VERSION "1"

NS_ :

BS_:

BU_: User ADM_PC_LF45

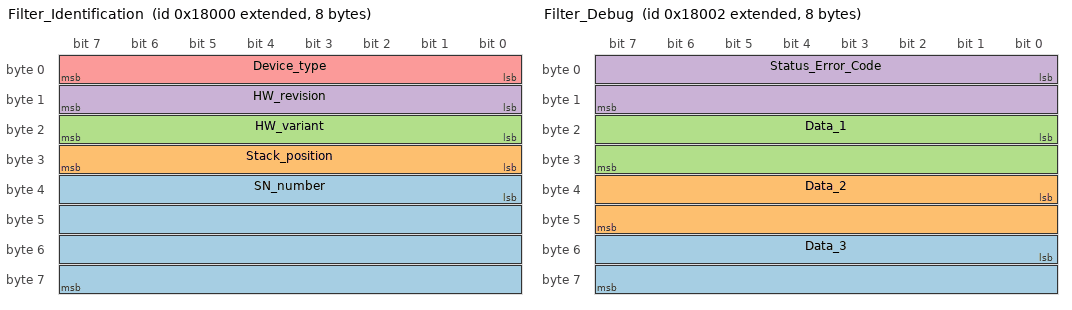
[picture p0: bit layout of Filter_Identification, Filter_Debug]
BO_ 2147581952 Filter_Identification: 8 ADM_PC_LF45
 SG_ SN_number : 32|32@1+ (1,0) [0|0] "" Vector__XXX
 SG_ Stack_position : 24|8@1+ (1,0) [0|0] "" Vector__XXX
 SG_ HW_variant : 16|8@1+ (1,0) [0|0] "" Vector__XXX
 SG_ HW_revision : 8|8@1+ (1,0) [0|0] "" Vector__XXX
 SG_ Device_type : 0|8@1+ (1,0) [0|0] "" Vector__XXX

BO_ 2147581953 Filter_FwInfo: 8 ADM_PC_LF45
 SG_ FW_info_mux M : 56|8@1+ (1,0) [0|0] "" Vector__XXX
 SG_ FW_datecode_13 m3 : 48|8@1+ (1,0) [0|0] "" Vector__XXX
 SG_ FW_datecode_6 m2 : 48|8@1+ (1,0) [0|0] "" Vector__XXX
 SG_ FW_revision_13 m1 : 48|8@1+ (1,0) [0|0] "" Vector__XXX
 SG_ FW_revision_6 m0 : 48|8@1+ (1,0) [0|0] "" Vector__XXX
 SG_ FW_datecode_12 m3 : 40|8@1+ (1,0) [0|0] "" Vector__XXX
 SG_ FW_datecode_5 m2 : 40|8@1+ (1,0) [0|0] "" Vector__XXX
 SG_ FW_revision_12 m1 : 40|8@1+ (1,0) [0|0] "" Vector__XXX
 SG_ FW_revision_5 m0 : 40|8@1+ (1,0) [0|0] "" Vector__XXX
 SG_ FW_datecode_11 m3 : 32|8@1+ (1,0) [0|0] "" Vector__XXX
 SG_ FW_datecode_4 m2 : 32|8@1+ (1,0) [0|0] "" Vector__XXX
 SG_ FW_revision_11 m1 : 32|8@1+ (1,0) [0|0] "" Vector__XXX
 SG_ FW_revision_4 m0 : 32|8@1+ (1,0) [0|0] "" Vector__XXX
 SG_ FW_datecode_10 m3 : 24|8@1+ (1,0) [0|0] "" Vector__XXX
 SG_ FW_datecode_3 m2 : 24|8@1+ (1,0) [0|0] "" Vector__XXX
 SG_ FW_revision_10 m1 : 24|8@1+ (1,0) [0|0] "" Vector__XXX
 SG_ FW_revision_3 m0 : 24|8@1+ (1,0) [0|0] "" Vector__XXX
 SG_ FW_datecode_9 m3 : 16|8@1+ (1,0) [0|0] "" Vector__XXX
 SG_ FW_datecode_2 m2 : 16|8@1+ (1,0) [0|0] "" Vector__XXX
 SG_ FW_revision_9 m1 : 16|8@1+ (1,0) [0|0] "" Vector__XXX
 SG_ FW_revision_2 m0 : 16|8@1+ (1,0) [0|0] "" Vector__XXX
 SG_ FW_datecode_8 m3 : 8|8@1+ (1,0) [0|0] "" Vector__XXX
 SG_ FW_datecode_1 m2 : 8|8@1+ (1,0) [0|0] "" Vector__XXX
 SG_ FW_revision_8 m1 : 8|8@1+ (1,0) [0|0] "" Vector__XXX
 SG_ FW_revision_1 m0 : 8|8@1+ (1,0) [0|0] "" Vector__XXX
 SG_ FW_datecode_7 m3 : 0|8@1+ (1,0) [0|0] "" Vector__XXX
 SG_ FW_datecode_0 m2 : 0|8@1+ (1,0) [0|0] "" Vector__XXX
 SG_ FW_revision_7 m1 : 0|8@1+ (1,0) [0|0] "" Vector__XXX
 SG_ FW_revision_0 m0 : 0|8@1+ (1,0) [0|0] "" Vector__XXX

BO_ 2147581965 _Filter_Boot_FwInfo: 8 ADM_PC_LF45
 SG_ Boot_FW_info_mux M : 56|8@1+ (1,0) [0|0] "" Vector__XXX
 SG_ FW_datecode_13 m3 : 48|8@1+ (1,0) [0|0] "" Vector__XXX
 SG_ FW_datecode_6 m2 : 48|8@1+ (1,0) [0|0] "" Vector__XXX
 SG_ FW_revision_13 m1 : 48|8@1+ (1,0) [0|0] "" Vector__XXX
 SG_ FW_revision_6 m0 : 48|8@1+ (1,0) [0|0] "" Vector__XXX
 SG_ FW_datecode_12 m3 : 40|8@1+ (1,0) [0|0] "" Vector__XXX
 SG_ FW_datecode_5 m2 : 40|8@1+ (1,0) [0|0] "" Vector__XXX
 SG_ FW_revision_12 m1 : 40|8@1+ (1,0) [0|0] "" Vector__XXX
 SG_ FW_revision_5 m0 : 40|8@1+ (1,0) [0|0] "" Vector__XXX
 SG_ FW_datecode_11 m3 : 32|8@1+ (1,0) [0|0] "" Vector__XXX
 SG_ FW_datecode_4 m2 : 32|8@1+ (1,0) [0|0] "" Vector__XXX
 SG_ FW_revision_11 m1 : 32|8@1+ (1,0) [0|0] "" Vector__XXX
 SG_ FW_revision_4 m0 : 32|8@1+ (1,0) [0|0] "" Vector__XXX
 SG_ FW_datecode_10 m3 : 24|8@1+ (1,0) [0|0] "" Vector__XXX
 SG_ FW_datecode_3 m2 : 24|8@1+ (1,0) [0|0] "" Vector__XXX
 SG_ FW_revision_10 m1 : 24|8@1+ (1,0) [0|0] "" Vector__XXX
 SG_ FW_revision_3 m0 : 24|8@1+ (1,0) [0|0] "" Vector__XXX
 SG_ FW_datecode_9 m3 : 16|8@1+ (1,0) [0|0] "" Vector__XXX
 SG_ FW_datecode_2 m2 : 16|8@1+ (1,0) [0|0] "" Vector__XXX
 SG_ FW_revision_9 m1 : 16|8@1+ (1,0) [0|0] "" Vector__XXX
 SG_ FW_revision_2 m0 : 16|8@1+ (1,0) [0|0] "" Vector__XXX
 SG_ FW_datecode_8 m3 : 8|8@1+ (1,0) [0|0] "" Vector__XXX
 SG_ FW_datecode_1 m2 : 8|8@1+ (1,0) [0|0] "" Vector__XXX
 SG_ FW_revision_8 m1 : 8|8@1+ (1,0) [0|0] "" Vector__XXX
 SG_ FW_revision_1 m0 : 8|8@1+ (1,0) [0|0] "" Vector__XXX
 SG_ FW_datecode_7 m3 : 0|8@1+ (1,0) [0|0] "" Vector__XXX
 SG_ FW_datecode_0 m2 : 0|8@1+ (1,0) [0|0] "" Vector__XXX
 SG_ FW_revision_7 m1 : 0|8@1+ (1,0) [0|0] "" Vector__XXX
 SG_ FW_revision_0 m0 : 0|8@1+ (1,0) [0|0] "" Vector__XXX

BO_ 2147581954 Filter_Debug: 8 ADM_PC_LF45
 SG_ Data_3 : 48|16@1+ (1,0) [0|0] "" Vector__XXX
 SG_ Data_2 : 32|16@1+ (1,0) [0|0] "" Vector__XXX
 SG_ Data_1 : 16|16@1+ (1,0) [0|0] "" Vector__XXX
 SG_ Status_Error_Code : 0|16@1+ (1,0) [0|0] "" Vector__XXX

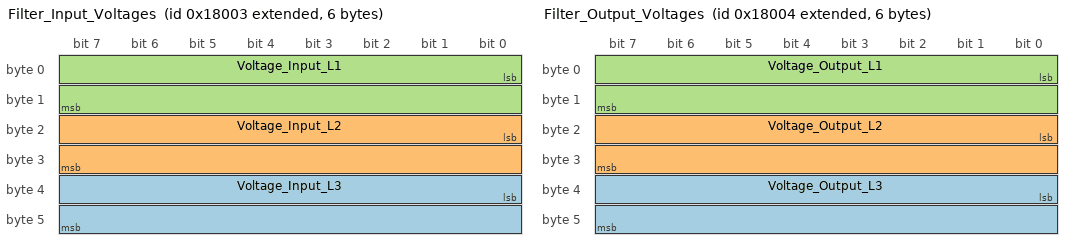
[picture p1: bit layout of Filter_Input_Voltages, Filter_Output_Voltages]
BO_ 2147581955 Filter_Input_Voltages: 6 ADM_PC_LF45
 SG_ Voltage_Input_L3 : 32|16@1+ (0.1,0) [0|0] "V" Vector__XXX
 SG_ Voltage_Input_L2 : 16|16@1+ (0.1,0) [0|0] "V" Vector__XXX
 SG_ Voltage_Input_L1 : 0|16@1+ (0.1,0) [0|0] "V" Vector__XXX

BO_ 2147581956 Filter_Output_Voltages: 6 ADM_PC_LF45
 SG_ Voltage_Output_L3 : 32|16@1+ (0.1,0) [0|0] "V" Vector__XXX
 SG_ Voltage_Output_L2 : 16|16@1+ (0.1,0) [0|0] "V" Vector__XXX
 SG_ Voltage_Output_L1 : 0|16@1+ (0.1,0) [0|0] "V" Vector__XXX

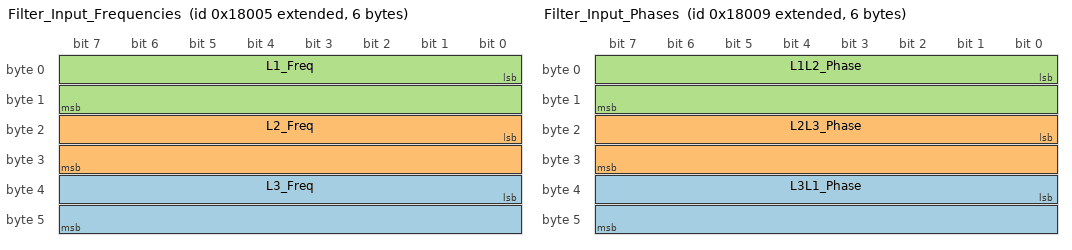
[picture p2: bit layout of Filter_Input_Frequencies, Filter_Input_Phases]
BO_ 2147581957 Filter_Input_Frequencies: 6 ADM_PC_LF45
 SG_ L3_Freq : 32|16@1+ (0.1,0) [0|0] "Hz" Vector__XXX
 SG_ L2_Freq : 16|16@1+ (0.1,0) [0|0] "Hz" Vector__XXX
 SG_ L1_Freq : 0|16@1+ (0.1,0) [0|0] "Hz" Vector__XXX

BO_ 2147581961 Filter_Input_Phases: 6 ADM_PC_LF45
 SG_ L3L1_Phase : 32|16@1+ (0.1,0) [0|0] "°" Vector__XXX
 SG_ L2L3_Phase : 16|16@1+ (0.1,0) [0|0] "°" Vector__XXX
 SG_ L1L2_Phase : 0|16@1+ (0.1,0) [0|0] "°" Vector__XXX

BO_ 2147581958 Filter_Temperature: 2 ADM_PC_LF45
 SG_ Temp_Inductor : 0|16@1- (0.01,0) [0|0] "°C" Vector__XXX

BO_ 2147581962 Filter_Supply_24V: 2 ADM_PC_LF45
 SG_ Supply_Voltage : 0|16@1+ (0.1,0) [0|0] "V" Vector__XXX

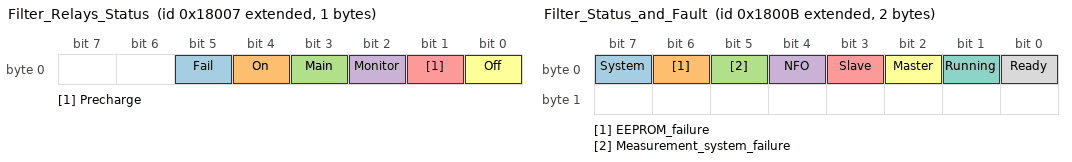
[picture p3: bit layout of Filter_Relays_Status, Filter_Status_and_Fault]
BO_ 2147581959 Filter_Relays_Status: 1 ADM_PC_LF45
 SG_ Fail : 5|1@1+ (1,0) [0|0] "" Vector__XXX
 SG_ On : 4|1@1+ (1,0) [0|0] "" Vector__XXX
 SG_ Main : 3|1@1+ (1,0) [0|0] "" Vector__XXX
 SG_ Monitor : 2|1@1+ (1,0) [0|0] "" Vector__XXX
 SG_ Precharge : 1|1@1+ (1,0) [0|0] "" Vector__XXX
 SG_ Off : 0|1@1+ (1,0) [0|0] "" Vector__XXX

BO_ 2147581963 Filter_Status_and_Fault: 2 ADM_PC_LF45
 SG_ System : 7|1@1+ (1,0) [0|0] "" Vector__XXX
 SG_ EEPROM_failure : 6|1@1+ (1,0) [0|0] "" Vector__XXX
 SG_ Measurement_system_failure : 5|1@1+ (1,0) [0|0] "" Vector__XXX
 SG_ NFO : 4|1@1+ (1,0) [0|0] "" Vector__XXX
 SG_ Slave : 3|1@1+ (1,0) [0|0] "" Vector__XXX
 SG_ Master : 2|1@1+ (1,0) [0|0] "" Vector__XXX
 SG_ Running : 1|1@1+ (1,0) [0|0] "" Vector__XXX
 SG_ Ready : 0|1@1+ (1,0) [0|0] "" Vector__XXX

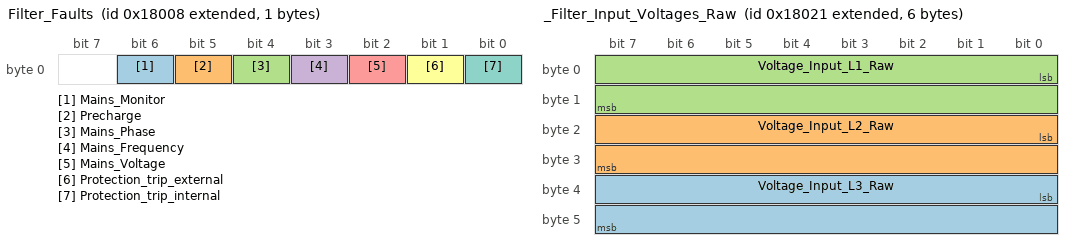
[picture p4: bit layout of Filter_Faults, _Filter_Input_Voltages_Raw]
BO_ 2147581960 Filter_Faults: 1 ADM_PC_LF45
 SG_ Mains_Monitor : 6|1@1+ (1,0) [0|0] "" Vector__XXX
 SG_ Precharge : 5|1@1+ (1,0) [0|0] "" Vector__XXX
 SG_ Mains_Phase : 4|1@1+ (1,0) [0|0] "" Vector__XXX
 SG_ Mains_Frequency : 3|1@1+ (1,0) [0|0] "" Vector__XXX
 SG_ Mains_Voltage : 2|1@1+ (1,0) [0|0] "" Vector__XXX
 SG_ Protection_trip_external : 1|1@1+ (1,0) [0|0] "" Vector__XXX
 SG_ Protection_trip_internal : 0|1@1+ (1,0) [0|0] "" Vector__XXX

BO_ 2147581985 _Filter_Input_Voltages_Raw: 6 ADM_PC_LF45
 SG_ Voltage_Input_L3_Raw : 32|16@1+ (1,0) [0|0] "ADC Counts" Vector__XXX
 SG_ Voltage_Input_L2_Raw : 16|16@1+ (1,0) [0|0] "ADC Counts" Vector__XXX
 SG_ Voltage_Input_L1_Raw : 0|16@1+ (1,0) [0|0] "ADC Counts" Vector__XXX

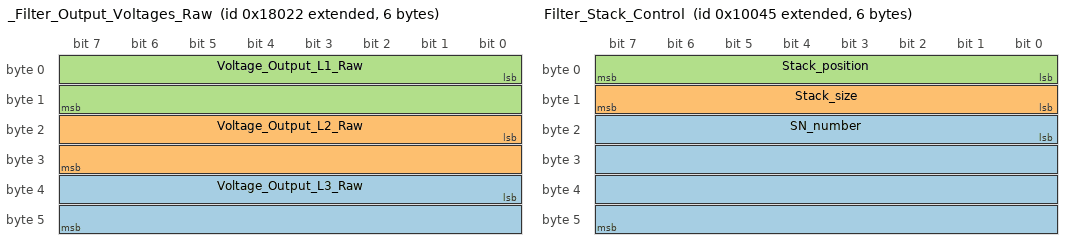
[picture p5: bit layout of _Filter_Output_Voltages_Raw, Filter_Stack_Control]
BO_ 2147581986 _Filter_Output_Voltages_Raw: 6 ADM_PC_LF45
 SG_ Voltage_Output_L3_Raw : 32|16@1+ (1,0) [0|0] "ADC Counts" Vector__XXX
 SG_ Voltage_Output_L2_Raw : 16|16@1+ (1,0) [0|0] "ADC Counts" Vector__XXX
 SG_ Voltage_Output_L1_Raw : 0|16@1+ (1,0) [0|0] "ADC Counts" Vector__XXX

BO_ 2147582016 Filter_Relays: 1 User
 SG_ Open_Relays : 1|1@1+ (1,0) [0|0] ""  ADM_PC_LF45
 SG_ Close_Relays : 0|1@1+ (1,0) [0|0] ""  ADM_PC_LF45

BO_ 2147549257 Filter_Independent_Relay_Control: 1 User
 SG_ Grid_Relay_ON : 1|1@1+ (1,0) [0|0] ""  ADM_PC_LF45
 SG_ Precharge_Relay_ON : 0|1@1+ (1,0) [0|0] ""  ADM_PC_LF45

BO_ 2147549264 Filter_Fault_Control: 1 User
 SG_ Reset_Processor : 1|1@1+ (1,0) [0|0] ""  ADM_PC_LF45
 SG_ Clear_Interlock : 0|1@1+ (1,0) [0|0] ""  ADM_PC_LF45

BO_ 2147549251 _Filter_Calibration_Offset_Updat: 6 User
 SG_ CRC : 32|16@1+ (1,0) [0|0] "-"  ADM_PC_LF45
 SG_ Calibration_Index M : 16|16@1+ (1,0) [0|0] "" Vector__XXX
 SG_ Voltage_Output_L3_Calib m5 : 0|16@1- (1,0) [0|0] "ADC Counts"  ADM_PC_LF45
 SG_ Voltage_Output_L2_Calib m4 : 0|16@1- (1,0) [0|0] "ADC Counts"  ADM_PC_LF45
 SG_ Voltage_Output_L1_Calib m3 : 0|16@1- (1,0) [0|0] "ADC Counts"  ADM_PC_LF45
 SG_ Voltage_Input_L3_Calib m2 : 0|16@1- (1,0) [0|0] "ADC Counts"  ADM_PC_LF45
 SG_ Voltage_Input_L2_Calib m1 : 0|16@1- (1,0) [0|0] "ADC Counts"  ADM_PC_LF45
 SG_ Voltage_Input_L1_Calib m0 : 0|16@1- (1,0) [0|0] "ADC Counts"  ADM_PC_LF45

BO_ 2147549252 _Filter_Calibration_Scale_Update: 6 User
 SG_ CRC : 32|16@1+ (1,0) [0|0] "-"  ADM_PC_LF45
 SG_ Calibration_Index M : 16|16@1+ (1,0) [0|0] "" Vector__XXX
 SG_ Voltage_Output_L3_Calib m5 : 0|16@1- (1.52587890625e-05,0) [0|0] "scale = 1.0 + value"  ADM_PC_LF45
 SG_ Voltage_Output_L2_Calib m4 : 0|16@1- (1.52587890625e-05,0) [0|0] "scale = 1.0 + value"  ADM_PC_LF45
 SG_ Voltage_Output_L1_Calib m3 : 0|16@1- (1.52587890625e-05,0) [0|0] "scale = 1.0 + value"  ADM_PC_LF45
 SG_ Voltage_Input_L3_Calib m2 : 0|16@1- (1.52587890625e-05,0) [0|0] "scale = 1.0 + value"  ADM_PC_LF45
 SG_ Voltage_Input_L2_Calib m1 : 0|16@1- (1.52587890625e-05,0) [0|0] "scale = 1.0 + value"  ADM_PC_LF45
 SG_ Voltage_Input_L1_Calib m0 : 0|16@1- (1.52587890625e-05,0) [0|0] "scale = 1.0 + value"  ADM_PC_LF45

BO_ 2147582019 _Filter_Calibration_Adc_Scale: 6 ADM_PC_LF45
 SG_ Adc_Index M : 32|16@1+ (1,0) [0|0] "" Vector__XXX
 SG_ Voltage_Output_L3 m5 : 0|32@1+ (1,0) [0|0] "1 / adc_bins"  User
 SG_ Voltage_Output_L2 m4 : 0|32@1+ (1,0) [0|0] "1 / adc_bins"  User
 SG_ Voltage_Output_L1 m3 : 0|32@1+ (1,0) [0|0] "1 / adc_bins"  User
 SG_ Voltage_Input_L3 m2 : 0|32@1+ (1,0) [0|0] "1 / adc_bins"  User
 SG_ Voltage_Input_L2 m1 : 0|32@1+ (1,0) [0|0] "1 / adc_bins"  User
 SG_ Voltage_Input_L1 m0 : 0|32@1+ (1,0) [0|0] "1 / adc_bins"  User

BO_ 2147582020 _Filter_Calibration_Adc_Fs: 6 ADM_PC_LF45
 SG_ Adc_Index M : 32|16@1+ (1,0) [0|0] "" Vector__XXX
 SG_ Voltage_Output_L3 m5 : 0|32@1+ (1,0) [0|0] "Fullscale"  User
 SG_ Voltage_Output_L2 m4 : 0|32@1+ (1,0) [0|0] "Fullscale"  User
 SG_ Voltage_Output_L1 m3 : 0|32@1+ (1,0) [0|0] "Fullscale"  User
 SG_ Voltage_Input_L3 m2 : 0|32@1+ (1,0) [0|0] "Fullscale"  User
 SG_ Voltage_Input_L2 m1 : 0|32@1+ (1,0) [0|0] "Fullscale"  User
 SG_ Voltage_Input_L1 m0 : 0|32@1+ (1,0) [0|0] "Fullscale"  User

BO_ 2147549253 Filter_Stack_Control: 6 User
 SG_ SN_number : 16|32@1+ (1,0) [0|0] ""  ADM_PC_LF45
 SG_ Stack_size : 8|8@1+ (1,0) [0|0] ""  ADM_PC_LF45
 SG_ Stack_position : 0|8@1+ (1,0) [0|0] ""  ADM_PC_LF45

BO_ 2147549281 Filter_System_Flags_Control: 8 User
 SG_ Factory_mode : 0|1@1+ (1,0) [0|0] ""  ADM_PC_LF45

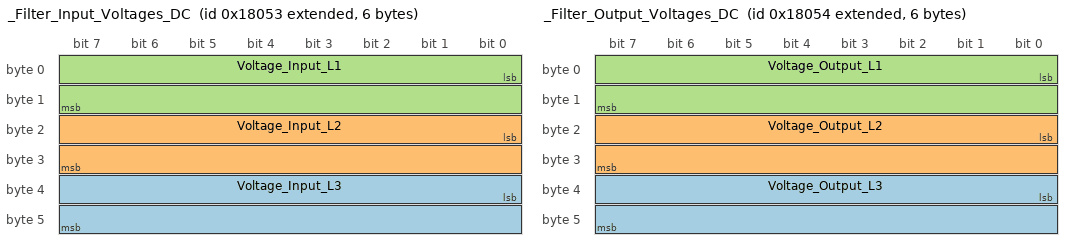
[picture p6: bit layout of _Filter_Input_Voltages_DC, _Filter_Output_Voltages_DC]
BO_ 2147582035 _Filter_Input_Voltages_DC: 6 ADM_PC_LF45
 SG_ Voltage_Input_L3 : 32|16@1+ (0.1,0) [0|0] "V" Vector__XXX
 SG_ Voltage_Input_L2 : 16|16@1+ (0.1,0) [0|0] "V" Vector__XXX
 SG_ Voltage_Input_L1 : 0|16@1+ (0.1,0) [0|0] "V" Vector__XXX

BO_ 2147582036 _Filter_Output_Voltages_DC: 6 ADM_PC_LF45
 SG_ Voltage_Output_L3 : 32|16@1+ (0.1,0) [0|0] "V" Vector__XXX
 SG_ Voltage_Output_L2 : 16|16@1+ (0.1,0) [0|0] "V" Vector__XXX
 SG_ Voltage_Output_L1 : 0|16@1+ (0.1,0) [0|0] "V" Vector__XXX

CM_ BO_ 2147581952 "Identification of the device";
CM_ SG_ 2147581952 SN_number "Unique module serial number";
CM_ SG_ 2147581952 Stack_position "Position of the module within the stack";
CM_ SG_ 2147581952 HW_variant "The DSP firmware revision number";
CM_ SG_ 2147581952 HW_revision "The hardware revision number";
CM_ SG_ 2147581952 Device_type "The device identification field, uniquely identifies the sender in the network";
CM_ BO_ 2147581953 "Git revision of the DSP firmware";
CM_ SG_ 2147581953 FW_datecode_13 "Character 13";
CM_ SG_ 2147581953 FW_datecode_6 "Character 3";
CM_ SG_ 2147581953 FW_revision_13 "Character 13";
CM_ SG_ 2147581953 FW_revision_6 "Character 3";
CM_ SG_ 2147581953 FW_datecode_12 "Character 12";
CM_ SG_ 2147581953 FW_datecode_5 "Character 3";
CM_ SG_ 2147581953 FW_revision_12 "Character 12";
CM_ SG_ 2147581953 FW_revision_5 "Character 3";
CM_ SG_ 2147581953 FW_datecode_11 "Character 11";
CM_ SG_ 2147581953 FW_datecode_4 "Character 3";
CM_ SG_ 2147581953 FW_revision_11 "Character 11";
CM_ SG_ 2147581953 FW_revision_4 "Character 3";
CM_ SG_ 2147581953 FW_datecode_10 "Character 10";
CM_ SG_ 2147581953 FW_datecode_3 "Character 3";
CM_ SG_ 2147581953 FW_revision_10 "Character 10";
CM_ SG_ 2147581953 FW_revision_3 "Character 3";
CM_ SG_ 2147581953 FW_datecode_9 "Character 9";
CM_ SG_ 2147581953 FW_datecode_2 "Character 2";
CM_ SG_ 2147581953 FW_revision_9 "Character 9";
CM_ SG_ 2147581953 FW_revision_2 "Character 2";
CM_ SG_ 2147581953 FW_datecode_8 "Character 8";
CM_ SG_ 2147581953 FW_datecode_1 "Character 1";
CM_ SG_ 2147581953 FW_revision_8 "Character 8";
CM_ SG_ 2147581953 FW_revision_1 "Character 1";
CM_ SG_ 2147581953 FW_datecode_7 "Character 7";
CM_ SG_ 2147581953 FW_datecode_0 "Character 0";
CM_ SG_ 2147581953 FW_revision_7 "Character 7";
CM_ SG_ 2147581953 FW_revision_0 "Character 0";
CM_ BO_ 2147581965 "Git revision of the bootloader firmware.";
CM_ SG_ 2147581965 FW_datecode_13 "Character 13";
CM_ SG_ 2147581965 FW_datecode_6 "Character 3";
CM_ SG_ 2147581965 FW_revision_13 "Character 13";
CM_ SG_ 2147581965 FW_revision_6 "Character 3";
CM_ SG_ 2147581965 FW_datecode_12 "Character 12";
CM_ SG_ 2147581965 FW_datecode_5 "Character 3";
CM_ SG_ 2147581965 FW_revision_12 "Character 12";
CM_ SG_ 2147581965 FW_revision_5 "Character 3";
CM_ SG_ 2147581965 FW_datecode_11 "Character 11";
CM_ SG_ 2147581965 FW_datecode_4 "Character 3";
CM_ SG_ 2147581965 FW_revision_11 "Character 11";
CM_ SG_ 2147581965 FW_revision_4 "Character 3";
CM_ SG_ 2147581965 FW_datecode_10 "Character 10";
CM_ SG_ 2147581965 FW_datecode_3 "Character 3";
CM_ SG_ 2147581965 FW_revision_10 "Character 10";
CM_ SG_ 2147581965 FW_revision_3 "Character 3";
CM_ SG_ 2147581965 FW_datecode_9 "Character 9";
CM_ SG_ 2147581965 FW_datecode_2 "Character 2";
CM_ SG_ 2147581965 FW_revision_9 "Character 9";
CM_ SG_ 2147581965 FW_revision_2 "Character 2";
CM_ SG_ 2147581965 FW_datecode_8 "Character 8";
CM_ SG_ 2147581965 FW_datecode_1 "Character 1";
CM_ SG_ 2147581965 FW_revision_8 "Character 8";
CM_ SG_ 2147581965 FW_revision_1 "Character 1";
CM_ SG_ 2147581965 FW_datecode_7 "Character 7";
CM_ SG_ 2147581965 FW_datecode_0 "Character 0";
CM_ SG_ 2147581965 FW_revision_7 "Character 7";
CM_ SG_ 2147581965 FW_revision_0 "Character 0";
CM_ BO_ 2147581954 "Values for debugging of HW/SW problems";
CM_ SG_ 2147581954 Data_3 "Additional information for the error/status";
CM_ SG_ 2147581954 Data_2 "Additional information for the error/status";
CM_ SG_ 2147581954 Data_1 "Additional information for the error/status";
CM_ SG_ 2147581954 Status_Error_Code "Main status / error code as defined in errno/errno.h";
CM_ BO_ 2147581955 "Input voltages readout. Realtime RMS readouts of the sensed variables. The voltage measured before the contactors.";
CM_ SG_ 2147581955 Voltage_Input_L3 "Voltage measured at the filter input, phase 3";
CM_ SG_ 2147581955 Voltage_Input_L2 "Voltage measured at the filter input, phase 2";
CM_ SG_ 2147581955 Voltage_Input_L1 "Voltage measured at the filter input, phase 1";
CM_ BO_ 2147581956 "Output voltages readout. Realtime RMS readouts of the sensed variables. The voltage measured after the contactors.";
CM_ SG_ 2147581956 Voltage_Output_L3 "Voltage measured at the filter output, phase 3";
CM_ SG_ 2147581956 Voltage_Output_L2 "Voltage measured at the filter output, phase 2";
CM_ SG_ 2147581956 Voltage_Output_L1 "Voltage measured at the filter output, phase 1";
CM_ BO_ 2147581957 "Input voltage frequencies>";
CM_ SG_ 2147581957 L3_Freq "Frequency measured at the filter input, phase 3";
CM_ SG_ 2147581957 L2_Freq "Frequency measured at the filter input, phase 2";
CM_ SG_ 2147581957 L1_Freq "Frequency measured at the filter input, phase 1";
CM_ BO_ 2147581961 "Input voltage frequencies>";
CM_ SG_ 2147581961 L3L1_Phase "Phase advance measured at the filter input, phase 3 to phase 1";
CM_ SG_ 2147581961 L2L3_Phase "Phase advance measured at the filter input, phase 2 to phase 3";
CM_ SG_ 2147581961 L1L2_Phase "Phase advance measured at the filter input, phase 1 to phase 2";
CM_ BO_ 2147581958 "Readouts of the module temperature sensor";
CM_ SG_ 2147581958 Temp_Inductor "Temperature of the inductor";
CM_ BO_ 2147581962 "Readouts of the 24-V supply voltage";
CM_ BO_ 2147581959 "State of the filter relays.";
CM_ BO_ 2147581963 "Status and fault bitfield";
CM_ BO_ 2147581960 "Fault bitfield";
CM_ SG_ 2147581960 Mains_Monitor "Grid health monitor is not ready";
CM_ SG_ 2147581960 Precharge "Precharge failed (check output voltage)";
CM_ SG_ 2147581960 Mains_Phase "Mains phase advance out of tolerance";
CM_ SG_ 2147581960 Mains_Frequency "Mains frequency out of tolerance";
CM_ SG_ 2147581960 Mains_Voltage "Mains voltage out of tolerance";
CM_ SG_ 2147581960 Protection_trip_external "This flag is asserted if the interlock is open due to an external condition received in the module.";
CM_ SG_ 2147581960 Protection_trip_internal "This flagg is asserted if the interlock is open due to an internal fault condition (self-protection)";
CM_ BO_ 2147581985 "Input voltages readout. Debug only values, for calibration";
CM_ SG_ 2147581985 Voltage_Input_L3_Raw "Voltage measured at the filter input, phase 3";
CM_ SG_ 2147581985 Voltage_Input_L2_Raw "Voltage measured at the filter input, phase 2";
CM_ SG_ 2147581985 Voltage_Input_L1_Raw "Voltage measured at the filter input, phase 1";
CM_ BO_ 2147581986 "Output voltages readout. Debug only values, for calibration";
CM_ SG_ 2147581986 Voltage_Output_L3_Raw "Voltage measured at the filter output, phase 3";
CM_ SG_ 2147581986 Voltage_Output_L2_Raw "Voltage measured at the filter output, phase 2";
CM_ SG_ 2147581986 Voltage_Output_L1_Raw "Voltage measured at the filter output, phase 1";
CM_ BO_ 2147582016 "Close or open Filter relays. Strobe controlled.";
CM_ SG_ 2147582016 Open_Relays "Command to open the relays.";
CM_ SG_ 2147582016 Close_Relays "Command to close the relays.";
CM_ BO_ 2147549257 "INTERNAL USE. User MUST NOT use this message under any circumstance. The user should instead
            use the \"Filter_Relays\" message to operate the LF45.";
CM_ SG_ 2147549257 Grid_Relay_ON "Internal use. User MUST NOT modify this";
CM_ SG_ 2147549257 Precharge_Relay_ON "Internal use. User MUST NOT modify this";
CM_ BO_ 2147549264 "Fault Control: actions to clear faults and reset the system";
CM_ SG_ 2147549264 Reset_Processor "Reset the filter DSP";
CM_ SG_ 2147549264 Clear_Interlock "Clears the filter interlock";
CM_ BO_ 2147549251 "Update of the calibration table for offsets.";
CM_ SG_ 2147549251 CRC "
                    Checksum of bytes 0 to 5, CRC-CCITT, corresponding to qChecksum (www.qt.io)
                ";
CM_ SG_ 2147549251 Voltage_Output_L3_Calib "Voltage offset at the converter output, phase 3";
CM_ SG_ 2147549251 Voltage_Output_L2_Calib "Voltage offset at the converter output, phase 2";
CM_ SG_ 2147549251 Voltage_Output_L1_Calib "Voltage offset at the converter output, phase 1";
CM_ SG_ 2147549251 Voltage_Input_L3_Calib "Voltage offset at the converter input, phase 3";
CM_ SG_ 2147549251 Voltage_Input_L2_Calib "Voltage offset at the converter input, phase 2";
CM_ SG_ 2147549251 Voltage_Input_L1_Calib "Voltage offset at the converter input, phase 1";
CM_ BO_ 2147549252 "Update of the calibration table for offsets.";
CM_ SG_ 2147549252 CRC "
                    Checksum of bytes 0 to 5, CRC-CCITT, corresponding to qChecksum (www.qt.io)
                ";
CM_ SG_ 2147549252 Voltage_Output_L3_Calib "Voltage offset at the converter output, phase 3";
CM_ SG_ 2147549252 Voltage_Output_L2_Calib "Voltage offset at the converter output, phase 2";
CM_ SG_ 2147549252 Voltage_Output_L1_Calib "Voltage offset at the converter output, phase 1";
CM_ SG_ 2147549252 Voltage_Input_L3_Calib "Voltage offset at the converter input, phase 3";
CM_ SG_ 2147549252 Voltage_Input_L2_Calib "Voltage offset at the converter input, phase 2";
CM_ SG_ 2147549252 Voltage_Input_L1_Calib "Voltage offset at the converter input, phase 1";
CM_ BO_ 2147582019 "
                Adc scale (resolution) value of readouts.
            ";
CM_ BO_ 2147582020 "
                Adc fullscale value of readouts.
            ";
CM_ BO_ 2147549253 "Filter stack control";
CM_ SG_ 2147549253 SN_number "Unique module serial number";
CM_ SG_ 2147549253 Stack_size "How many Filter converters are in stack in total";
CM_ SG_ 2147549253 Stack_position "The converter position within the stack";
CM_ BO_ 2147549281 "Control the system flags";
CM_ SG_ 2147549281 Factory_mode "Customers MUST NOT USE this bit. If set to 1, module will enter in factory mode. ";
CM_ BO_ 2147582035 "Input voltages readout. Realtime readouts of the sensed variables. The voltage measured before the contactors.";
CM_ SG_ 2147582035 Voltage_Input_L3 "Voltage measured at the filter input, phase 3";
CM_ SG_ 2147582035 Voltage_Input_L2 "Voltage measured at the filter input, phase 2";
CM_ SG_ 2147582035 Voltage_Input_L1 "Voltage measured at the filter input, phase 1";
CM_ BO_ 2147582036 "Output voltages readout. Realtime RMS readouts of the sensed variables. The voltage measured after the contactors.";
CM_ SG_ 2147582036 Voltage_Output_L3 "Voltage measured at the filter output, phase 3";
CM_ SG_ 2147582036 Voltage_Output_L2 "Voltage measured at the filter output, phase 2";
CM_ SG_ 2147582036 Voltage_Output_L1 "Voltage measured at the filter output, phase 1";
BA_DEF_ BO_  "SystemMessageLongSymbol" STRING ;
BA_DEF_ BO_  "GenMsgCycleTime" INT 0 65535;
BA_DEF_DEF_  "SystemMessageLongSymbol" "";
BA_DEF_DEF_  "GenMsgCycleTime" 0;
BA_ "GenMsgCycleTime" BO_ 2147581952 1000;
BA_ "GenMsgCycleTime" BO_ 2147581953 1000;
BA_ "GenMsgCycleTime" BO_ 2147581965 1000;
BA_ "GenMsgCycleTime" BO_ 2147581954 1000;
BA_ "GenMsgCycleTime" BO_ 2147581955 100;
BA_ "GenMsgCycleTime" BO_ 2147581956 100;
BA_ "GenMsgCycleTime" BO_ 2147581957 100;
BA_ "GenMsgCycleTime" BO_ 2147581961 100;
BA_ "GenMsgCycleTime" BO_ 2147581958 1000;
BA_ "GenMsgCycleTime" BO_ 2147581962 1000;
BA_ "GenMsgCycleTime" BO_ 2147581959 100;
BA_ "GenMsgCycleTime" BO_ 2147581963 100;
BA_ "GenMsgCycleTime" BO_ 2147581960 100;
BA_ "GenMsgCycleTime" BO_ 2147581985 100;
BA_ "GenMsgCycleTime" BO_ 2147581986 100;
BA_ "GenMsgCycleTime" BO_ 2147582016 100;
BA_ "SystemMessageLongSymbol" BO_ 2147549251 "_Filter_Calibration_Offset_Update";
BA_ "GenMsgCycleTime" BO_ 2147582019 1000;
BA_ "GenMsgCycleTime" BO_ 2147582020 1000;
BA_ "GenMsgCycleTime" BO_ 2147582035 100;
BA_ "GenMsgCycleTime" BO_ 2147582036 100;
VAL_ 2147581952 Device_type 1 "Filter" ;
VAL_ 2147581963 System 1 "fault" ;
VAL_ 2147581963 EEPROM_failure 1 "fault" ;
VAL_ 2147581963 Measurement_system_failure 1 "fault" ;
VAL_ 2147581963 NFO 1 "fault" ;
VAL_ 2147581960 Mains_Monitor 1 "fault" ;
VAL_ 2147581960 Precharge 1 "fault" ;
VAL_ 2147581960 Mains_Phase 1 "fault" ;
VAL_ 2147581960 Mains_Frequency 1 "fault" ;
VAL_ 2147581960 Mains_Voltage 1 "fault" ;
VAL_ 2147581960 Protection_trip_external 1 "fault" ;
VAL_ 2147581960 Protection_trip_internal 1 "fault" ;
SIG_VALTYPE_ 2147582019 Voltage_Input_L1 : 1;
SIG_VALTYPE_ 2147582019 Voltage_Input_L2 : 1;
SIG_VALTYPE_ 2147582019 Voltage_Input_L3 : 1;
SIG_VALTYPE_ 2147582019 Voltage_Output_L1 : 1;
SIG_VALTYPE_ 2147582019 Voltage_Output_L2 : 1;
SIG_VALTYPE_ 2147582019 Voltage_Output_L3 : 1;
SIG_VALTYPE_ 2147582020 Voltage_Input_L1 : 1;
SIG_VALTYPE_ 2147582020 Voltage_Input_L2 : 1;
SIG_VALTYPE_ 2147582020 Voltage_Input_L3 : 1;
SIG_VALTYPE_ 2147582020 Voltage_Output_L1 : 1;
SIG_VALTYPE_ 2147582020 Voltage_Output_L2 : 1;
SIG_VALTYPE_ 2147582020 Voltage_Output_L3 : 1;
